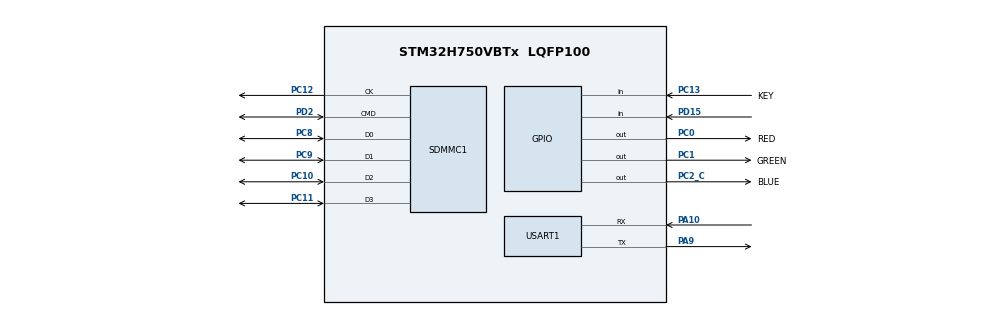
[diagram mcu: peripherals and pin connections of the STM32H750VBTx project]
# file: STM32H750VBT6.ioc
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CORTEX_M7.CPU_DCache=Enabled
CORTEX_M7.CPU_ICache=Enabled
CORTEX_M7.MPU_Control=__NULL
Mcu.Family=STM32H7
Mcu.Name=STM32H750VBTx
Mcu.Package=LQFP100
NVIC.PriorityGroup=NVIC_PRIORITYGROUP_2
NVIC.USART1_IRQn=true\:0\:0\:false\:false\:true\:true\:true
PA10.Mode=Asynchronous
PA10.Signal=USART1_RX
PA13\ (JTMS/SWDIO).Mode=Serial_Wire
PA13\ (JTMS/SWDIO).Signal=DEBUG_JTMS-SWDIO
PA14\ (JTCK/SWCLK).Mode=Serial_Wire
PA14\ (JTCK/SWCLK).Signal=DEBUG_JTCK-SWCLK
PA9.Mode=Asynchronous
PA9.Signal=USART1_TX
PC0.GPIO_Label=RED
PC0.GPIO_PuPd=GPIO_PULLUP
PC0.PinState=GPIO_PIN_SET
PC0.Signal=GPIO_Output
PC1.GPIO_Label=GREEN
PC1.GPIO_PuPd=GPIO_PULLUP
PC1.GPIO_Speed=GPIO_SPEED_FREQ_LOW
PC1.PinState=GPIO_PIN_SET
PC1.Signal=GPIO_Output
PC10.Mode=SD_4_bits_Wide_bus
PC10.Signal=SDMMC1_D2
PC11.Mode=SD_4_bits_Wide_bus
PC11.Signal=SDMMC1_D3
PC12.Mode=SD_4_bits_Wide_bus
PC12.Signal=SDMMC1_CK
PC13.GPIO_Label=KEY
PC13.GPIO_PuPd=GPIO_PULLUP
PC13.Signal=GPIO_Input
PC14-OSC32_IN\ (OSC32_IN).Mode=LSE-External-Oscillator
PC14-OSC32_IN\ (OSC32_IN).Signal=RCC_OSC32_IN
PC15-OSC32_OUT\ (OSC32_OUT).Mode=LSE-External-Oscillator
PC15-OSC32_OUT\ (OSC32_OUT).Signal=RCC_OSC32_OUT
PC2_C.GPIO_Label=BLUE
PC2_C.GPIO_PuPd=GPIO_PULLUP
PC2_C.PinState=GPIO_PIN_SET
PC2_C.Signal=GPIO_Output
PC8.Mode=SD_4_bits_Wide_bus
PC8.Signal=SDMMC1_D0
PC9.Mode=SD_4_bits_Wide_bus
PC9.Signal=SDMMC1_D1
PD15.Signal=GPIO_Input
PD2.Mode=SD_4_bits_Wide_bus
PD2.Signal=SDMMC1_CMD
PH0-OSC_IN\ (PH0).Mode=HSE-External-Oscillator
PH0-OSC_IN\ (PH0).Signal=RCC_OSC_IN
PH1-OSC_OUT\ (PH1).Mode=HSE-External-Oscillator
PH1-OSC_OUT\ (PH1).Signal=RCC_OSC_OUT
ProjectManager.HeapSize=0x800
ProjectManager.StackSize=0x800
ProjectManager.TargetToolchain=MDK-ARM V5
RCC.ADCFreq_Value=480000000
RCC.APB1Freq_Value=120000000
RCC.APB2Freq_Value=120000000
RCC.APB3Freq_Value=120000000
RCC.APB4Freq_Value=120000000
RCC.CortexFreq_Value=480000000
RCC.D1PPRE=RCC_APB3_DIV2
RCC.D2PPRE1=RCC_APB1_DIV2
RCC.D2PPRE2=RCC_APB2_DIV2
RCC.D3PPRE=RCC_APB4_DIV2
RCC.DIVM1=1
RCC.DIVM2=1
RCC.DIVM3=1
RCC.DIVN1=80
RCC.DIVN2=80
RCC.DIVN3=80
RCC.DIVQ1=6
RCC.FLatency=FLASH_LATENCY_4
RCC.HCLKFreq_Value=240000000
RCC.HPRE=RCC_HCLK_DIV2
RCC.HSE_VALUE=12000000
RCC.PLLFRACN=0
RCC.PLLSourceVirtual=RCC_PLLSOURCE_HSE
RCC.PWR_Regulator_Voltage_Scale=PWR_REGULATOR_VOLTAGE_SCALE0
RCC.ProductRev=revV
RCC.SYSCLKFreq_VALUE=480000000
RCC.SYSCLKSource=RCC_SYSCLKSOURCE_PLLCLK
RCC.USBFreq_Value=160000000
SDMMC1.ClockDiv=10
USART1.VirtualMode-Asynchronous=VM_ASYNC
VP_FATFS_VS_SDIO.Mode=SDIO
board=custom

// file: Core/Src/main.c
/* USER CODE BEGIN Header */
/**
  ******************************************************************************
  * @file           : main.c
  * @brief          : Main program body
  ******************************************************************************
  * @attention
  *
  * <h2><center>&copy; Copyright (c) 2021 STMicroelectronics.
  * All rights reserved.</center></h2>
  *
  * This software component is licensed by ST under BSD 3-Clause license,
  * the "License"; You may not use this file except in compliance with the
  * License. You may obtain a copy of the License at:
  *                        opensource.org/licenses/BSD-3-Clause
  *
  ******************************************************************************
  */
/* USER CODE END Header */
#include "main.h"
#include "fatfs.h"
#include "sdmmc.h"
#include "usart.h"
#include "gpio.h"

/* USER CODE BEGIN Includes */
#include "BSP_GPIO.h"
#include "BSP_USART.h"
/* USER CODE END Includes */

void SystemClock_Config(void);

int main(void)
{

  /* Enable I-Cache---------------------------------------------------------*/
  SCB_EnableICache();

  /* Enable D-Cache---------------------------------------------------------*/
  SCB_EnableDCache();

  /* MCU Configuration--------------------------------------------------------*/

  /* Reset of all peripherals, Initializes the Flash interface and the Systick. */
  HAL_Init();

  /* Configure the system clock */
  SystemClock_Config();

  /* Initialize all configured peripherals */
  MX_GPIO_Init();
  MX_USART1_UART_Init();
  MX_SDMMC1_SD_Init();
  MX_FATFS_Init();
  /* USER CODE BEGIN 2 */

	HAL_UART_Receive_IT(&huart1, &rx1_buf, 1);

  /* USER CODE END 2 */

  /* Infinite loop */
  /* USER CODE BEGIN WHILE */
  while (1)
  {
		LED_R_TogglePin;
		HAL_Delay(500);
    /* USER CODE END WHILE */

  }
}

void SystemClock_Config(void)
{
  RCC_OscInitTypeDef RCC_OscInitStruct = {0};
  RCC_ClkInitTypeDef RCC_ClkInitStruct = {0};

  /** Supply configuration update enable
  */
  HAL_PWREx_ConfigSupply(PWR_LDO_SUPPLY);
  /** Configure the main internal regulator output voltage
  */
  __HAL_PWR_VOLTAGESCALING_CONFIG(PWR_REGULATOR_VOLTAGE_SCALE0);

  while(!__HAL_PWR_GET_FLAG(PWR_FLAG_VOSRDY)) {}
  /** Initializes the RCC Oscillators according to the specified parameters
  * in the RCC_OscInitTypeDef structure.
  */
  RCC_OscInitStruct.OscillatorType = RCC_OSCILLATORTYPE_HSE;
  RCC_OscInitStruct.HSEState = RCC_HSE_ON;
  RCC_OscInitStruct.PLL.PLLState = RCC_PLL_ON;
  RCC_OscInitStruct.PLL.PLLSource = RCC_PLLSOURCE_HSE;
  RCC_OscInitStruct.PLL.PLLM = 1;
  RCC_OscInitStruct.PLL.PLLN = 80;
  RCC_OscInitStruct.PLL.PLLP = 2;
  RCC_OscInitStruct.PLL.PLLQ = 6;
  RCC_OscInitStruct.PLL.PLLR = 2;
  RCC_OscInitStruct.PLL.PLLRGE = RCC_PLL1VCIRANGE_3;
  RCC_OscInitStruct.PLL.PLLVCOSEL = RCC_PLL1VCOWIDE;
  RCC_OscInitStruct.PLL.PLLFRACN = 0;
  if (HAL_RCC_OscConfig(&RCC_OscInitStruct) != HAL_OK)
  {
    Error_Handler();
  }
  /** Initializes the CPU, AHB and APB buses clocks
  */
  RCC_ClkInitStruct.ClockType = RCC_CLOCKTYPE_HCLK|RCC_CLOCKTYPE_SYSCLK
                              |RCC_CLOCKTYPE_PCLK1|RCC_CLOCKTYPE_PCLK2
                              |RCC_CLOCKTYPE_D3PCLK1|RCC_CLOCKTYPE_D1PCLK1;
  RCC_ClkInitStruct.SYSCLKSource = RCC_SYSCLKSOURCE_PLLCLK;
  RCC_ClkInitStruct.SYSCLKDivider = RCC_SYSCLK_DIV1;
  RCC_ClkInitStruct.AHBCLKDivider = RCC_HCLK_DIV2;
  RCC_ClkInitStruct.APB3CLKDivider = RCC_APB3_DIV2;
  RCC_ClkInitStruct.APB1CLKDivider = RCC_APB1_DIV2;
  RCC_ClkInitStruct.APB2CLKDivider = RCC_APB2_DIV2;
  RCC_ClkInitStruct.APB4CLKDivider = RCC_APB4_DIV2;

  if (HAL_RCC_ClockConfig(&RCC_ClkInitStruct, FLASH_LATENCY_4) != HAL_OK)
  {
    Error_Handler();
  }
}

void Error_Handler(void)
{
  __disable_irq();
  while (1)
  {
  }
}

/************************ (C) COPYRIGHT STMicroelectronics *****END OF FILE****/
